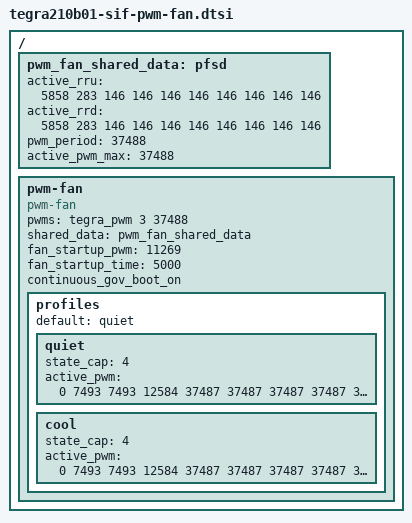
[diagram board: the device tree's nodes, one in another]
/*
 * Copyright (c) 2019, NVIDIA CORPORATION.  All rights reserved.
 *
 * This program is free software; you can redistribute it and/or modify it
 * under the terms and conditions of the GNU General Public License,
 * version 2, as published by the Free Software Foundation.
 *
 * This program is distributed in the hope it will be useful, but WITHOUT
 * ANY WARRANTY; without even the implied warranty of MERCHANTABILITY or
 * FITNESS FOR A PARTICULAR PURPOSE.  See the GNU General Public License for
 * more details.
 */

#include "foster-platforms/tegra210-pwm-fan-p2530-0930.dtsi"

/ {
	pwm_fan_shared_data: pfsd {
		active_rru = <5858 283 146 146 146 146 146 146 146 146>;
		active_rrd = <5858 283 146 146 146 146 146 146 146 146>;
		pwm_period = <37488>;
		active_pwm_max = <37488>;
	};

	pwm-fan {
		compatible = "pwm-fan";
		status = "okay";
		pwms = <&tegra_pwm 3 37488>;
		shared_data = <&pwm_fan_shared_data>;
		fan_startup_pwm = <11269>; /* For DVT SIF, 30% of max pwm */
		fan_startup_time = <5000>;
		continuous_gov_boot_on;
		profiles {
			default = "quiet";
			quiet {
				state_cap = <4>;
				active_pwm = <0 7493 7493 12584 37487 37487 37487 37487 37487 37487>;
			};
			cool {
				state_cap = <4>;
				active_pwm = <0 7493 7493 12584 37487 37487 37487 37487 37487 37487>;
			};
		};
	};
};
